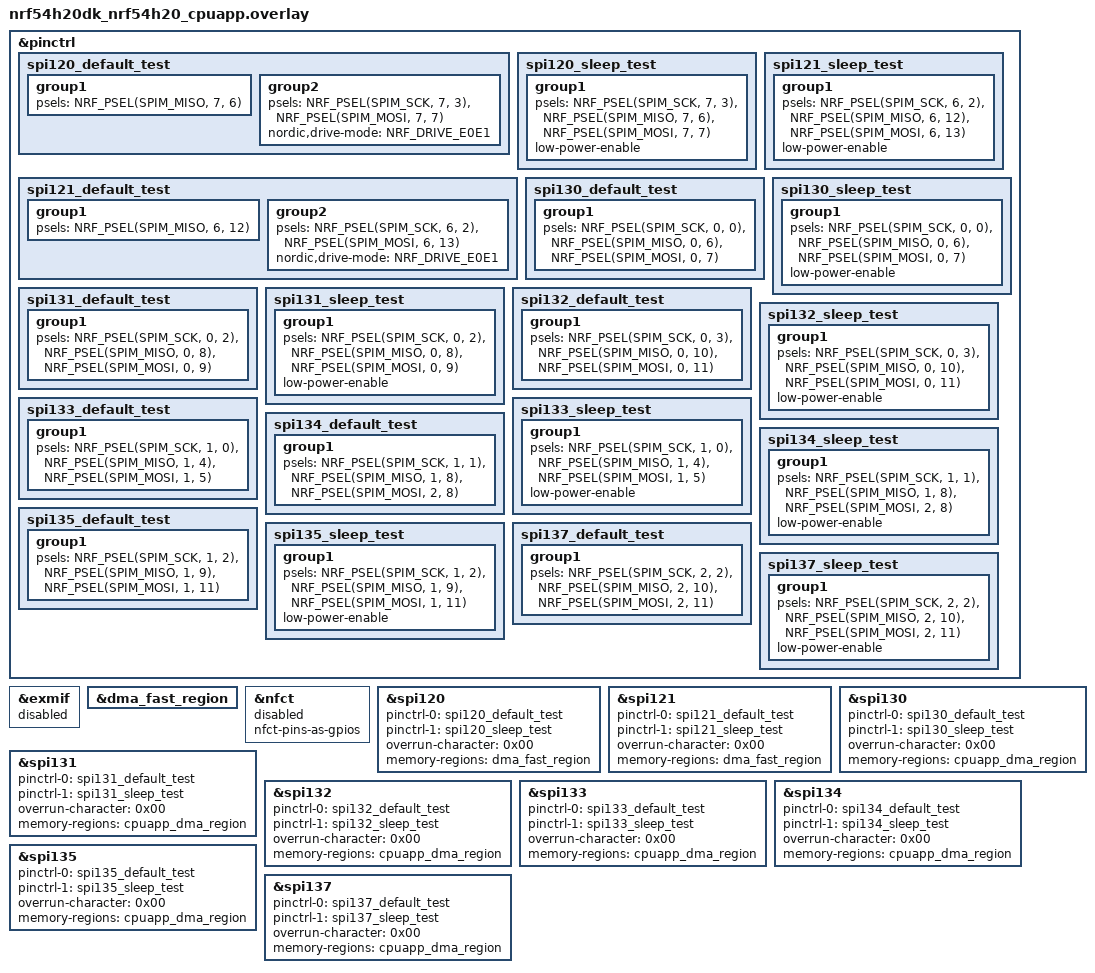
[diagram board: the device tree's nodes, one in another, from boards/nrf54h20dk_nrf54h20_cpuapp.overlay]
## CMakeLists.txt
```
# SPDX-License-Identifier: LicenseRef-Nordic-5-Clause

cmake_minimum_required(VERSION 3.20.0)

find_package(Zephyr REQUIRED HINTS $ENV{ZEPHYR_BASE})
project(spim_instances)

FILE(GLOB app_sources src/*.c)
target_sources(app PRIVATE ${app_sources})
```

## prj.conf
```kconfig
CONFIG_ZTEST=y
CONFIG_TEST_USERSPACE=y
CONFIG_SPI=y
CONFIG_LOG=y
```

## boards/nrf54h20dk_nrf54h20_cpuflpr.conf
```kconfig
# Copyright (c) 2026 Nordic Semiconductor ASA
#
# SPDX-License-Identifier: LicenseRef-Nordic-5-Clause

# nRF54H20 FLPR has no GPIO interrupts available
CONFIG_GPIO_NRFX_INTERRUPT=n
CONFIG_NRFX_GPIOTE=y
```

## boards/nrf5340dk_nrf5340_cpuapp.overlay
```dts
/*
 * Copyright (c) 2026 Nordic Semiconductor ASA
 *
 * SPDX-License-Identifier: LicenseRef-Nordic-5-Clause
 */

&pinctrl {
	spi1_default_test: spi1_default_test {
		group1 {
			psels = <NRF_PSEL(SPIM_SCK, 0, 6)>,
				<NRF_PSEL(SPIM_MISO, 1, 8)>,
				<NRF_PSEL(SPIM_MOSI, 1, 9)>;
		};
	};

	spi1_sleep_test: spi1_sleep_test {
		group1 {
			psels = <NRF_PSEL(SPIM_SCK, 0, 6)>,
				<NRF_PSEL(SPIM_MISO, 1, 8)>,
				<NRF_PSEL(SPIM_MOSI, 1, 9)>;
			low-power-enable;
		};
	};

	spi2_default_test: spi2_default_test {
		group1 {
			psels = <NRF_PSEL(SPIM_SCK, 1, 5)>,
				<NRF_PSEL(SPIM_MISO, 1, 6)>,
				<NRF_PSEL(SPIM_MOSI, 1, 7)>;
		};
	};

	spi2_sleep_test: spi2_sleep_test {
		group1 {
			psels = <NRF_PSEL(SPIM_SCK, 1, 5)>,
				<NRF_PSEL(SPIM_MISO, 1, 6)>,
				<NRF_PSEL(SPIM_MOSI, 1, 7)>;
			low-power-enable;
		};
	};
};

/delete-node/ &mx25r64;

&spi1 {
	status = "okay";
	pinctrl-0 = <&spi1_default_test>;
	pinctrl-1 = <&spi1_sleep_test>;
	pinctrl-names = "default", "sleep";
	overrun-character = <0x00>;
};

&spi2 {
	status = "okay";
	pinctrl-0 = <&spi2_default_test>;
	pinctrl-1 = <&spi2_sleep_test>;
	pinctrl-names = "default", "sleep";
	overrun-character = <0x00>;
};
```

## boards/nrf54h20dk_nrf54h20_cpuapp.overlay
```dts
/*
 * Copyright (c) 2025 Nordic Semiconductor ASA
 *
 * SPDX-License-Identifier: LicenseRef-Nordic-5-Clause
 */

&pinctrl {
	spi120_default_test: spi120_default_test {
		group1 {
			psels = <NRF_PSEL(SPIM_MISO, 7, 6)>;
		};

		group2 {
			psels = <NRF_PSEL(SPIM_SCK, 7, 3)>,
				<NRF_PSEL(SPIM_MOSI, 7, 7)>;
			nordic,drive-mode = <NRF_DRIVE_E0E1>;
		};
	};

	spi120_sleep_test: spi120_sleep_test {
		group1 {
			psels = <NRF_PSEL(SPIM_SCK, 7, 3)>,
				<NRF_PSEL(SPIM_MISO, 7, 6)>,
				<NRF_PSEL(SPIM_MOSI, 7, 7)>;
			low-power-enable;
		};
	};

	spi121_default_test: spi121_default_test {
		group1 {
			psels = <NRF_PSEL(SPIM_MISO, 6, 12)>;
		};

		group2 {
			psels = <NRF_PSEL(SPIM_SCK, 6, 2)>,
				<NRF_PSEL(SPIM_MOSI, 6, 13)>;
			nordic,drive-mode = <NRF_DRIVE_E0E1>;
		};
	};

	spi121_sleep_test: spi121_sleep_test {
		group1 {
			psels = <NRF_PSEL(SPIM_SCK, 6, 2)>,
				<NRF_PSEL(SPIM_MISO, 6, 12)>,
				<NRF_PSEL(SPIM_MOSI, 6, 13)>;
			low-power-enable;
		};
	};

	spi130_default_test: spi130_default_test {
		group1 {
			psels = <NRF_PSEL(SPIM_SCK, 0, 0)>,
				<NRF_PSEL(SPIM_MISO, 0, 6)>,
				<NRF_PSEL(SPIM_MOSI, 0, 7)>;
		};
	};

	spi130_sleep_test: spi130_sleep_test {
		group1 {
			psels = <NRF_PSEL(SPIM_SCK, 0, 0)>,
				<NRF_PSEL(SPIM_MISO, 0, 6)>,
				<NRF_PSEL(SPIM_MOSI, 0, 7)>;
			low-power-enable;
		};
	};

	spi131_default_test: spi131_default_test {
		group1 {
			psels = <NRF_PSEL(SPIM_SCK, 0, 2)>,
				<NRF_PSEL(SPIM_MISO, 0, 8)>,
				<NRF_PSEL(SPIM_MOSI, 0, 9)>;
		};
	};

	spi131_sleep_test: spi131_sleep_test {
		group1 {
			psels = <NRF_PSEL(SPIM_SCK, 0, 2)>,
				<NRF_PSEL(SPIM_MISO, 0, 8)>,
				<NRF_PSEL(SPIM_MOSI, 0, 9)>;
			low-power-enable;
		};
	};

	spi132_default_test: spi132_default_test {
		group1 {
			psels = <NRF_PSEL(SPIM_SCK, 0, 3)>,
				<NRF_PSEL(SPIM_MISO, 0, 10)>,
				<NRF_PSEL(SPIM_MOSI, 0, 11)>;
		};
	};

	spi132_sleep_test: spi132_sleep_test {
		group1 {
			psels = <NRF_PSEL(SPIM_SCK, 0, 3)>,
				<NRF_PSEL(SPIM_MISO, 0, 10)>,
				<NRF_PSEL(SPIM_MOSI, 0, 11)>;
			low-power-enable;
		};
	};

	spi133_default_test: spi133_default_test {
		group1 {
			psels = <NRF_PSEL(SPIM_SCK, 1, 0)>,
				<NRF_PSEL(SPIM_MISO, 1, 4)>,
				<NRF_PSEL(SPIM_MOSI, 1, 5)>;
		};
	};

	spi133_sleep_test: spi133_sleep_test {
		group1 {
			psels = <NRF_PSEL(SPIM_SCK, 1, 0)>,
				<NRF_PSEL(SPIM_MISO, 1, 4)>,
				<NRF_PSEL(SPIM_MOSI, 1, 5)>;
			low-power-enable;
		};
	};

	spi134_default_test: spi134_default_test {
		group1 {
			psels = <NRF_PSEL(SPIM_SCK, 1, 1)>,
				<NRF_PSEL(SPIM_MISO, 1, 8)>,
				<NRF_PSEL(SPIM_MOSI, 2, 8)>;
		};
	};

	spi134_sleep_test: spi134_sleep_test {
		group1 {
			psels = <NRF_PSEL(SPIM_SCK, 1, 1)>,
				<NRF_PSEL(SPIM_MISO, 1, 8)>,
				<NRF_PSEL(SPIM_MOSI, 2, 8)>;
			low-power-enable;
		};
	};

	spi135_default_test: spi135_default_test {
		group1 {
			psels = <NRF_PSEL(SPIM_SCK, 1, 2)>,
				<NRF_PSEL(SPIM_MISO, 1, 9)>,
				<NRF_PSEL(SPIM_MOSI, 1, 11)>;
		};
	};

	spi135_sleep_test: spi135_sleep_test {
		group1 {
			psels = <NRF_PSEL(SPIM_SCK, 1, 2)>,
				<NRF_PSEL(SPIM_MISO, 1, 9)>,
				<NRF_PSEL(SPIM_MOSI, 1, 11)>;
			low-power-enable;
		};
	};

	spi137_default_test: spi137_default_test {
		group1 {
			psels = <NRF_PSEL(SPIM_SCK, 2, 2)>,
				<NRF_PSEL(SPIM_MISO, 2, 10)>,
				<NRF_PSEL(SPIM_MOSI, 2, 11)>;
		};
	};

	spi137_sleep_test: spi137_sleep_test {
		group1 {
			psels = <NRF_PSEL(SPIM_SCK, 2, 2)>,
				<NRF_PSEL(SPIM_MISO, 2, 10)>,
				<NRF_PSEL(SPIM_MOSI, 2, 11)>;
			low-power-enable;
		};
	};
};

&exmif {
	status = "disabled";
};

&dma_fast_region {
	status = "okay";
};

&nfct {
	status = "disabled";
	nfct-pins-as-gpios;
};

&spi120 {
	status = "okay";
	pinctrl-0 = <&spi120_default_test>;
	pinctrl-1 = <&spi120_sleep_test>;
	pinctrl-names = "default", "sleep";
	overrun-character = <0x00>;
	memory-regions = <&dma_fast_region>;
};

&spi121 {
	status = "okay";
	pinctrl-0 = <&spi121_default_test>;
	pinctrl-1 = <&spi121_sleep_test>;
	pinctrl-names = "default", "sleep";
	overrun-character = <0x00>;
	memory-regions = <&dma_fast_region>;
};

&spi130 {
	status = "okay";
	pinctrl-0 = <&spi130_default_test>;
	pinctrl-1 = <&spi130_sleep_test>;
	pinctrl-names = "default", "sleep";
	overrun-character = <0x00>;
	memory-regions = <&cpuapp_dma_region>;
};

&spi131 {
	status = "okay";
	pinctrl-0 = <&spi131_default_test>;
	pinctrl-1 = <&spi131_sleep_test>;
	pinctrl-names = "default", "sleep";
	overrun-character = <0x00>;
	memory-regions = <&cpuapp_dma_region>;
};

&spi132 {
	status = "okay";
	pinctrl-0 = <&spi132_default_test>;
	pinctrl-1 = <&spi132_sleep_test>;
	pinctrl-names = "default", "sleep";
	overrun-character = <0x00>;
	memory-regions = <&cpuapp_dma_region>;
};

&spi133 {
	status = "okay";
	pinctrl-0 = <&spi133_default_test>;
	pinctrl-1 = <&spi133_sleep_test>;
	pinctrl-names = "default", "sleep";
	overrun-character = <0x00>;
	memory-regions = <&cpuapp_dma_region>;
};

&spi134 {
	status = "okay";
	pinctrl-0 = <&spi134_default_test>;
	pinctrl-1 = <&spi134_sleep_test>;
	pinctrl-names = "default", "sleep";
	overrun-character = <0x00>;
	memory-regions = <&cpuapp_dma_region>;
};

&spi135 {
	status = "okay";
	pinctrl-0 = <&spi135_default_test>;
	pinctrl-1 = <&spi135_sleep_test>;
	pinctrl-names = "default", "sleep";
	overrun-character = <0x00>;
	memory-regions = <&cpuapp_dma_region>;
};

/* spi136 inaccessible due to console on uart136 */

&spi137 {
	status = "okay";
	pinctrl-0 = <&spi137_default_test>;
	pinctrl-1 = <&spi137_sleep_test>;
	pinctrl-names = "default", "sleep";
	overrun-character = <0x00>;
	memory-regions = <&cpuapp_dma_region>;
};
```

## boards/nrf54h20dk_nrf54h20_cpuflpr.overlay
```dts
/*
 * Copyright (c) 2026 Nordic Semiconductor ASA
 *
 * SPDX-License-Identifier: LicenseRef-Nordic-5-Clause
 */

&pinctrl {
	spi120_default_test: spi120_default_test {
		group1 {
			psels = <NRF_PSEL(SPIM_MISO, 7, 6)>;
		};

		group2 {
			psels = <NRF_PSEL(SPIM_SCK, 7, 3)>,
				<NRF_PSEL(SPIM_MOSI, 7, 7)>;
			nordic,drive-mode = <NRF_DRIVE_E0E1>;
		};
	};

	spi120_sleep_test: spi120_sleep_test {
		group1 {
			psels = <NRF_PSEL(SPIM_SCK, 7, 3)>,
				<NRF_PSEL(SPIM_MISO, 7, 6)>,
				<NRF_PSEL(SPIM_MOSI, 7, 7)>;
			low-power-enable;
		};
	};

	spi121_default_test: spi121_default_test {
		group1 {
			psels = <NRF_PSEL(SPIM_MISO, 6, 12)>;
		};

		group2 {
			psels = <NRF_PSEL(SPIM_SCK, 6, 2)>,
				<NRF_PSEL(SPIM_MOSI, 6, 13)>;
			nordic,drive-mode = <NRF_DRIVE_E0E1>;
		};
	};

	spi121_sleep_test: spi121_sleep_test {
		group1 {
			psels = <NRF_PSEL(SPIM_SCK, 6, 2)>,
				<NRF_PSEL(SPIM_MISO, 6, 12)>,
				<NRF_PSEL(SPIM_MOSI, 6, 13)>;
			low-power-enable;
		};
	};
};

&gpio6 {
	status = "okay";
};

&gpio7 {
	status = "okay";
};

&dma_fast_region {
	status = "okay";
};

&spi120 {
	status = "okay";
	pinctrl-0 = <&spi120_default_test>;
	pinctrl-1 = <&spi120_sleep_test>;
	pinctrl-names = "default", "sleep";
	overrun-character = <0x00>;
	memory-regions = <&dma_fast_region>;
};

&spi121 {
	status = "okay";
	pinctrl-0 = <&spi121_default_test>;
	pinctrl-1 = <&spi121_sleep_test>;
	pinctrl-names = "default", "sleep";
	overrun-character = <0x00>;
	memory-regions = <&dma_fast_region>;
};

&uart120 {
	status = "disabled";
};
```

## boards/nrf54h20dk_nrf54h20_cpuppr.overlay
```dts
/*
 * Copyright (c) 2025 Nordic Semiconductor ASA
 *
 * SPDX-License-Identifier: LicenseRef-Nordic-5-Clause
 */

&pinctrl {
	spi130_default_test: spi130_default_test {
		group1 {
			psels = <NRF_PSEL(SPIM_SCK, 0, 0)>,
				<NRF_PSEL(SPIM_MISO, 0, 6)>,
				<NRF_PSEL(SPIM_MOSI, 0, 7)>;
		};
	};

	spi130_sleep_test: spi130_sleep_test {
		group1 {
			psels = <NRF_PSEL(SPIM_SCK, 0, 0)>,
				<NRF_PSEL(SPIM_MISO, 0, 6)>,
				<NRF_PSEL(SPIM_MOSI, 0, 7)>;
			low-power-enable;
		};
	};

	spi131_default_test: spi131_default_test {
		group1 {
			psels = <NRF_PSEL(SPIM_SCK, 0, 2)>,
				<NRF_PSEL(SPIM_MISO, 0, 8)>,
				<NRF_PSEL(SPIM_MOSI, 0, 9)>;
		};
	};

	spi131_sleep_test: spi131_sleep_test {
		group1 {
			psels = <NRF_PSEL(SPIM_SCK, 0, 2)>,
				<NRF_PSEL(SPIM_MISO, 0, 8)>,
				<NRF_PSEL(SPIM_MOSI, 0, 9)>;
			low-power-enable;
		};
	};

	spi132_default_test: spi132_default_test {
		group1 {
			psels = <NRF_PSEL(SPIM_SCK, 0, 3)>,
				<NRF_PSEL(SPIM_MISO, 0, 10)>,
				<NRF_PSEL(SPIM_MOSI, 0, 11)>;
		};
	};

	spi132_sleep_test: spi132_sleep_test {
		group1 {
			psels = <NRF_PSEL(SPIM_SCK, 0, 3)>,
				<NRF_PSEL(SPIM_MISO, 0, 10)>,
				<NRF_PSEL(SPIM_MOSI, 0, 11)>;
			low-power-enable;
		};
	};

	spi133_default_test: spi133_default_test {
		group1 {
			psels = <NRF_PSEL(SPIM_SCK, 1, 0)>,
				<NRF_PSEL(SPIM_MISO, 1, 4)>,
				<NRF_PSEL(SPIM_MOSI, 1, 5)>;
		};
	};

	spi133_sleep_test: spi133_sleep_test {
		group1 {
			psels = <NRF_PSEL(SPIM_SCK, 1, 0)>,
				<NRF_PSEL(SPIM_MISO, 1, 4)>,
				<NRF_PSEL(SPIM_MOSI, 1, 5)>;
			low-power-enable;
		};
	};

	spi134_default_test: spi134_default_test {
		group1 {
			psels = <NRF_PSEL(SPIM_SCK, 1, 1)>,
				<NRF_PSEL(SPIM_MISO, 1, 8)>,
				<NRF_PSEL(SPIM_MOSI, 2, 8)>;
		};
	};

	spi134_sleep_test: spi134_sleep_test {
		group1 {
			psels = <NRF_PSEL(SPIM_SCK, 1, 1)>,
				<NRF_PSEL(SPIM_MISO, 1, 8)>,
				<NRF_PSEL(SPIM_MOSI, 2, 8)>;
			low-power-enable;
		};
	};

	spi137_default_test: spi137_default_test {
		group1 {
			psels = <NRF_PSEL(SPIM_SCK, 2, 2)>,
				<NRF_PSEL(SPIM_MISO, 2, 10)>,
				<NRF_PSEL(SPIM_MOSI, 2, 11)>;
		};
	};

	spi137_sleep_test: spi137_sleep_test {
		group1 {
			psels = <NRF_PSEL(SPIM_SCK, 2, 2)>,
				<NRF_PSEL(SPIM_MISO, 2, 10)>,
				<NRF_PSEL(SPIM_MOSI, 2, 11)>;
			low-power-enable;
		};
	};
};

&gpio0 {
	status = "okay";
};

&gpio1 {
	status = "okay";
};

&gpio2 {
	status = "okay";
};

&gpiote130 {
	status = "okay";
	owned-channels = <7>;
};

/* PPR does not have interrupts for fast peripherals spi120 and spi121. */

&spi130 {
	compatible = "nordic,nrf-spim";
	status = "okay";
	pinctrl-0 = <&spi130_default_test>;
	pinctrl-1 = <&spi130_sleep_test>;
	pinctrl-names = "default", "sleep";
	overrun-character = <0x00>;
	zephyr,pm-device-runtime-auto;
};

&spi131 {
	status = "okay";
	pinctrl-0 = <&spi131_default_test>;
	pinctrl-1 = <&spi131_sleep_test>;
	pinctrl-names = "default", "sleep";
	overrun-character = <0x00>;
};

&spi132 {
	status = "okay";
	pinctrl-0 = <&spi132_default_test>;
	pinctrl-1 = <&spi132_sleep_test>;
	pinctrl-names = "default", "sleep";
	overrun-character = <0x00>;
};

&spi133 {
	status = "okay";
	pinctrl-0 = <&spi133_default_test>;
	pinctrl-1 = <&spi133_sleep_test>;
	pinctrl-names = "default", "sleep";
	overrun-character = <0x00>;
};

&spi134 {
	status = "okay";
	pinctrl-0 = <&spi134_default_test>;
	pinctrl-1 = <&spi134_sleep_test>;
	pinctrl-names = "default", "sleep";
	overrun-character = <0x00>;
};

/* spi135 inaccessible due to cpuppr console on uart135 */

/* spi136 inaccessible due to cpuapp console on uart136 */

&spi137 {
	status = "okay";
	pinctrl-0 = <&spi137_default_test>;
	pinctrl-1 = <&spi137_sleep_test>;
	pinctrl-names = "default", "sleep";
	overrun-character = <0x00>;
};
```

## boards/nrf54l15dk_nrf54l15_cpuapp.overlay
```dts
/*
 * Copyright (c) 2025 Nordic Semiconductor ASA
 *
 * SPDX-License-Identifier: LicenseRef-Nordic-5-Clause
 */

&pinctrl {
	spi00_default_test: spi00_default_test {
		group1 {
			psels = <NRF_PSEL(SPIM_MISO, 2, 9)>;
		};

		group2 {
			psels = <NRF_PSEL(SPIM_SCK, 2, 6)>,
				<NRF_PSEL(SPIM_MOSI, 2, 8)>;
			nordic,drive-mode = <NRF_DRIVE_E0E1>;
		};
	};

	spi00_sleep_test: spi00_sleep_test {
		group1 {
			psels = <NRF_PSEL(SPIM_SCK, 2, 6)>,
				<NRF_PSEL(SPIM_MISO, 2, 9)>,
				<NRF_PSEL(SPIM_MOSI, 2, 8)>;
			low-power-enable;
		};
	};

	spi21_default_test: spi21_default_test {
		group1 {
			psels = <NRF_PSEL(SPIM_SCK, 1, 12)>,
				<NRF_PSEL(SPIM_MISO, 1, 10)>,
				<NRF_PSEL(SPIM_MOSI, 1, 8)>;
		};
	};

	spi21_sleep_test: spi21_sleep_test {
		group1 {
			psels = <NRF_PSEL(SPIM_SCK, 1, 12)>,
				<NRF_PSEL(SPIM_MISO, 1, 10)>,
				<NRF_PSEL(SPIM_MOSI, 1, 8)>;
			low-power-enable;
		};
	};

	spi22_default_test: spi22_default_test {
		group1 {
			psels = <NRF_PSEL(SPIM_SCK, 1, 13)>,
				<NRF_PSEL(SPIM_MISO, 1, 11)>,
				<NRF_PSEL(SPIM_MOSI, 1, 9)>;
		};
	};

	spi22_sleep_test: spi22_sleep_test {
		group1 {
			psels = <NRF_PSEL(SPIM_SCK, 1, 13)>,
				<NRF_PSEL(SPIM_MISO, 1, 11)>,
				<NRF_PSEL(SPIM_MOSI, 1, 9)>;
			low-power-enable;
		};
	};

	spi30_default_test: spi30_default_test {
		group1 {
			psels = <NRF_PSEL(SPIM_SCK, 0, 0)>,
				<NRF_PSEL(SPIM_MISO, 0, 3)>,
				<NRF_PSEL(SPIM_MOSI, 0, 4)>;
		};
	};

	spi30_sleep_test: spi30_sleep_test {
		group1 {
			psels = <NRF_PSEL(SPIM_SCK, 0, 0)>,
				<NRF_PSEL(SPIM_MISO, 0, 3)>,
				<NRF_PSEL(SPIM_MOSI, 0, 4)>;
			low-power-enable;
		};
	};
};

/delete-node/ &mx25r64;

&spi00 {
	status = "okay";
	pinctrl-0 = <&spi00_default_test>;
	pinctrl-1 = <&spi00_sleep_test>;
	pinctrl-names = "default", "sleep";
	overrun-character = <0x00>;
};

/* spi20 inaccessible due to console on uart20 */

&spi21 {
	status = "okay";
	pinctrl-0 = <&spi21_default_test>;
	pinctrl-1 = <&spi21_sleep_test>;
	pinctrl-names = "default", "sleep";
	overrun-character = <0x00>;
};

&spi22 {
	status = "okay";
	pinctrl-0 = <&spi22_default_test>;
	pinctrl-1 = <&spi22_sleep_test>;
	pinctrl-names = "default", "sleep";
	overrun-character = <0x00>;
};

&spi30 {
	status = "okay";
	pinctrl-0 = <&spi30_default_test>;
	pinctrl-1 = <&spi30_sleep_test>;
	pinctrl-names = "default", "sleep";
	overrun-character = <0x00>;
};
```

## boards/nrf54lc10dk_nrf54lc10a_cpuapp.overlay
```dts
/*
 * Copyright (c) 2026 Nordic Semiconductor ASA
 *
 * SPDX-License-Identifier: LicenseRef-Nordic-5-Clause
 */

/*
 * Pinmux for nRF54LC10 DK (avoid DK buttons/LEDs and uart30 console on gpio0).
 * spi30 is not used (same address domain as uart30 used for console).
 */

&pinctrl {
	spi20_default_test: spi20_default_test {
		group1 {
			psels = <NRF_PSEL(SPIM_SCK, 1, 11)>,
				<NRF_PSEL(SPIM_MISO, 1, 12)>,
				<NRF_PSEL(SPIM_MOSI, 1, 13)>;
		};
	};

	spi20_sleep_test: spi20_sleep_test {
		group1 {
			psels = <NRF_PSEL(SPIM_SCK, 1, 11)>,
				<NRF_PSEL(SPIM_MISO, 1, 12)>,
				<NRF_PSEL(SPIM_MOSI, 1, 13)>;
			low-power-enable;
		};
	};

	spi21_default_test: spi21_default_test {
		group1 {
			psels = <NRF_PSEL(SPIM_SCK, 1, 14)>,
				<NRF_PSEL(SPIM_MISO, 1, 15)>,
				<NRF_PSEL(SPIM_MOSI, 1, 16)>;
		};
	};

	spi21_sleep_test: spi21_sleep_test {
		group1 {
			psels = <NRF_PSEL(SPIM_SCK, 1, 14)>,
				<NRF_PSEL(SPIM_MISO, 1, 15)>,
				<NRF_PSEL(SPIM_MOSI, 1, 16)>;
			low-power-enable;
		};
	};
};

&spi20 {
	status = "okay";
	pinctrl-0 = <&spi20_default_test>;
	pinctrl-1 = <&spi20_sleep_test>;
	pinctrl-names = "default", "sleep";
	overrun-character = <0x00>;
};

&spi21 {
	status = "okay";
	pinctrl-0 = <&spi21_default_test>;
	pinctrl-1 = <&spi21_sleep_test>;
	pinctrl-names = "default", "sleep";
	overrun-character = <0x00>;
};
```

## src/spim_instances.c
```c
/*
 * Copyright (c) 2025, Nordic Semiconductor ASA
 *
 * SPDX-License-Identifier: LicenseRef-Nordic-5-Clause
 */

#include <zephyr/kernel.h>
#include <zephyr/drivers/spi.h>
#include <zephyr/ztest.h>
#include <dmm.h>

#include <zephyr/logging/log.h>
LOG_MODULE_REGISTER(test);

#define DEVICE_DT_GET_AND_COMMA(node_id) DEVICE_DT_GET(node_id),
/* Generate a list of devices for all instances of the "compat" */
#define DEVS_FOR_DT_COMPAT(compat) \
	DT_FOREACH_STATUS_OKAY(compat, DEVICE_DT_GET_AND_COMMA)

static const struct device *const devices[] = {
#ifdef CONFIG_NRFX_SPIM
	DEVS_FOR_DT_COMPAT(nordic_nrf_spim)
#endif
};

typedef void (*test_func_t)(const struct device *dev);
typedef bool (*capability_func_t)(const struct device *dev);


#define DATA_FIELD (16)

static struct spi_config default_spi_cfg = {
	.frequency = 4000000,
	.operation = (SPI_OP_MODE_CONTROLLER | SPI_MODE_CPOL | SPI_WORD_SET(8) | SPI_LINES_SINGLE),
};

static void setup_instance(const struct device *dev)
{
	/* Left for future test expansion. */
}

static void tear_down_instance(const struct device *dev)
{
	/* Left for future test expansion. */
}

static void test_all_instances(test_func_t func, capability_func_t capability_check)
{
	int devices_skipped = 0;

	zassert_true(ARRAY_SIZE(devices) > 0, "No device found");
	for (int i = 0; i < ARRAY_SIZE(devices); i++) {
		setup_instance(devices[i]);
		TC_PRINT("\nInstance %u: ", i + 1);
		if ((capability_check == NULL) ||
		     capability_check(devices[i])) {
			TC_PRINT("Testing %s\n", devices[i]->name);
			func(devices[i]);
		} else {
			TC_PRINT("Skipped for %s\n", devices[i]->name);
			devices_skipped++;
		}
		tear_down_instance(devices[i]);
		/* Allow logs to be printed. */
		k_sleep(K_MSEC(100));
	}
	if (devices_skipped == ARRAY_SIZE(devices)) {
		ztest_test_skip();
	}
}


/**
 * Test validates if instance can transceive data.
 */
static void test_transceive_data_instance(const struct device *dev)
{
	static uint8_t spim_buffer[2 * DATA_FIELD] DMM_MEMORY_SECTION(DT_BUS(dev));
	int ret = 0;

	/* SPI buffer sets */
	struct spi_buf tx_spi_buf = {.buf = &spim_buffer[0], .len = DATA_FIELD};
	struct spi_buf_set tx_spi_buf_set = {.buffers = &tx_spi_buf, .count = 1};

	struct spi_buf rx_spi_buf = {.buf = &spim_buffer[DATA_FIELD],
				     .len = DATA_FIELD};
	struct spi_buf_set rx_spi_buf_set = {.buffers = &rx_spi_buf, .count = 1};

	ret = spi_transceive(dev, &default_spi_cfg, &tx_spi_buf_set, &rx_spi_buf_set);

	zassert_equal(0, ret, "%s: Unexpected error", dev->name);
}

static bool test_transceive_data_capable(const struct device *dev)
{
	return true;
}

ZTEST(spim_instances, test_transceive_data)
{
	test_all_instances(test_transceive_data_instance, test_transceive_data_capable);
}

static void *suite_setup(void)
{
	int i;

	for (i = 0; i < ARRAY_SIZE(devices); i++) {
		zassert_true(device_is_ready(devices[i]),
			     "Device %s is not ready", devices[i]->name);
		k_object_access_grant(devices[i], k_current_get());
	}

	return NULL;
}

ZTEST_SUITE(spim_instances, NULL, suite_setup, NULL, NULL, NULL);
```
